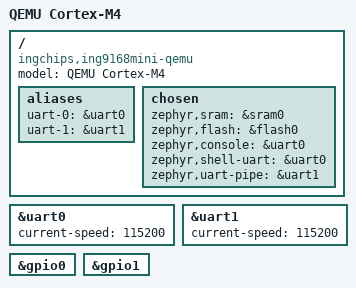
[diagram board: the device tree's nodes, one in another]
/* SPDX-License-Identifier: Apache-2.0 */

/dts-v1/;

#include <ingchips/ing9168.dtsi>

/ {
	model = "QEMU Cortex-M4";
	compatible = "ingchips,ing9168mini-qemu", "ingchips,ing9168mini";

	aliases {
		uart-0 = &uart0;
		uart-1 = &uart1;
	};

	chosen {
		zephyr,sram = &sram0;
		zephyr,flash = &flash0;
		zephyr,console = &uart0;
		zephyr,shell-uart = &uart0;
		zephyr,uart-pipe = &uart1;
	};
};

&uart0 {
	status = "okay";
	current-speed = <115200>;
};

&uart1 {
	status = "okay";
	current-speed = <115200>;
};

&gpio0 {
	status = "okay";
};

&gpio1 {
	status = "okay";
};

// &i2c0 {
// 	pinctrl-0 = <&i2c3_scl_pc0 &i2c3_sda_pc1>;
// 	status = "okay";
// };

